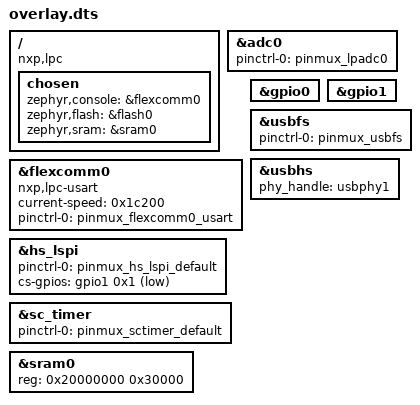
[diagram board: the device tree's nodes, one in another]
/ {
	compatible = "nxp,lpc", "nxp,lpc55xxx";
	chosen {
		zephyr,console = &flexcomm0;
		zephyr,flash = &flash0;
		zephyr,sram = &sram0;
	};
};
&adc0{
	status = "okay";
	pinctrl-0 = < &pinmux_lpadc0 >;
	pinctrl-names = "default";
};
&flexcomm0{
	compatible = "nxp,lpc-usart";
	status = "okay";
	current-speed = < 0x1c200 >;
	pinctrl-0 = < &pinmux_flexcomm0_usart >;
	pinctrl-names = "default";
};
&gpio0{
	status = "okay";
};
&gpio1{
	status = "okay";
};
&hs_lspi{
	status = "okay";
	pinctrl-0 = < &pinmux_hs_lspi_default >;
	pinctrl-names = "default";
	cs-gpios = < &gpio1 0x1 0x1 >;
};
&sc_timer{
	status = "okay";
	pinctrl-0 = < &pinmux_sctimer_default >;
	pinctrl-names = "default";
};
&sram0{
	reg = < 0x20000000 0x30000 >;
};
&usbfs{
	pinctrl-0 = < &pinmux_usbfs >;
	pinctrl-names = "default";
};
&usbhs{
	status = "okay";
	phy_handle = < &usbphy1 >;
};
